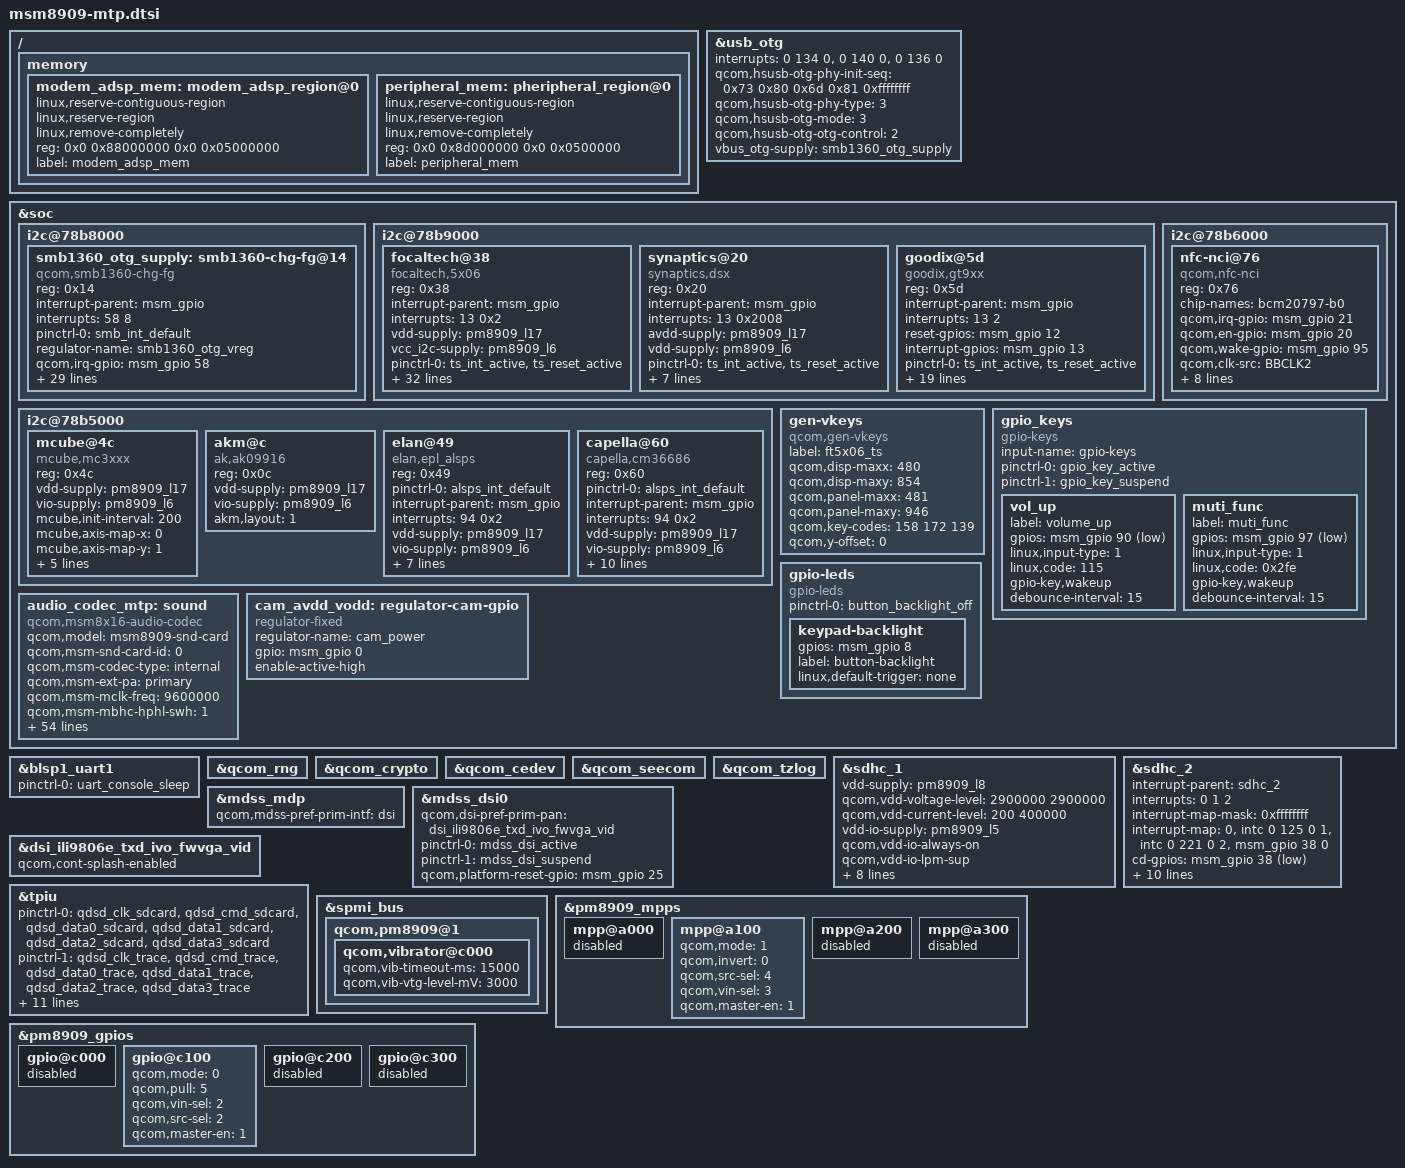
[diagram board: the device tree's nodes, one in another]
/* Copyright (c) 2014, The Linux Foundation. All rights reserved.
 *
 * This program is free software; you can redistribute it and/or modify
 * it under the terms of the GNU General Public License version 2 and
 * only version 2 as published by the Free Software Foundation.
 *
 * This program is distributed in the hope that it will be useful,
 * but WITHOUT ANY WARRANTY; without even the implied warranty of
 * MERCHANTABILITY or FITNESS FOR A PARTICULAR PURPOSE.  See the
 * GNU General Public License for more details.
 */

#include "msm8909-pinctrl.dtsi"
#include "msm8909-camera-sensor-mtp.dtsi"
#include "dsi-panel-ili9806e-txd-ivo-fwvga-video.dtsi"

/ {
	memory {
		#address-cells = <2>;
		#size-cells = <2>;

		modem_adsp_mem: modem_adsp_region@0 {
			linux,reserve-contiguous-region;
			linux,reserve-region;
			linux,remove-completely;
			reg = <0x0 0x88000000 0x0 0x05000000>;
			label = "modem_adsp_mem";
		};

		peripheral_mem: pheripheral_region@0 {
			linux,reserve-contiguous-region;
			linux,reserve-region;
			linux,remove-completely;
			reg = <0x0 0x8d000000 0x0 0x0500000>;
			label = "peripheral_mem";
		};
	};
};

&usb_otg {
    interrupts = <0 134 0>,<0 140 0>,<0 136 0>;
    interrupt-names = "core_irq", "async_irq", "phy_irq";

    qcom,hsusb-otg-phy-init-seq = <0x73 0x80 0x6d 0x81 0xffffffff>;
    qcom,hsusb-otg-phy-type = <3>; /* SNPS Femto PHY */
    qcom,hsusb-otg-mode = <3>; /* USB OTG */
    qcom,hsusb-otg-otg-control = <2>; /* PMIC */
    vbus_otg-supply = <&smb1360_otg_supply>;
};

&soc {
	i2c@78b8000 {
		smb1360_otg_supply: smb1360-chg-fg@14 {
			compatible = "qcom,smb1360-chg-fg";
			reg = <0x14>;
			interrupt-parent = <&msm_gpio>;
			interrupts = <58 8>;
			pinctrl-names = "default";
			pinctrl-0 = <&smb_int_default>;
			regulator-name = "smb1360_otg_vreg";
			qcom,irq-gpio = <&msm_gpio 58 0x8>;
			qcom,chg-inhibit-disabled;
			qcom,rsense-10mhom;
			qcom,otg-batt-curr-limit = <1500>;
			qcom,otg-batt-uvlo-thresh = <3300>;
			qcom,cpu0-sensor-name = "tsens_tz_sensor3";
			qcom,qpnp-vadc = <&pm8909_vadc>;
			qcom,float-voltage-mv = <4350>;
			qcom,iterm-ma = <100>;
			qcom,recharge-thresh-mv = <100>;
			qcom,thermal-mitigation = <1500 700 600 0>;
			qcom,charging-timeout = <1536>;
			qcom,fg-cutoff-voltage-mv = <3400>;
			qcom,fg-voltage-empty-mv = <3250>;
			qcom,fg-batt-capacity-mah = <3000>;
			qcom,fg-cc-soc-coeff = <0x8176>;
			qcom,fg-auto-recharge-soc = <99>;
			qcom,fg-reset-thresold-mv = <50>;
			qcom,shdn-after-pwroff;
			qcom,fg-reset-at-pon;
			qcom,config-hard-thresholds;
			qcom,cold-bat-decidegc = <(-80)>;
			qcom,hot-bat-decidegc = <560>;
			qcom,soft-jeita-supported;
			qcom,warm-bat-decidegc = <450>;
			qcom,cool-bat-decidegc = <100>;
			qcom,cool-bat-mv = <4350>;
			qcom,warm-bat-mv = <4350>;
			qcom,cool-bat-ma = <600>;
			qcom,warm-bat-ma = <900>;
		};
	};
	i2c@78b9000 { /* BLSP1 QUP5 */
		focaltech@38 {
			compatible = "focaltech,5x06";
			reg = <0x38>;
			interrupt-parent = <&msm_gpio>;
			interrupts = <13 0x2>;
			vdd-supply = <&pm8909_l17>;
			vcc_i2c-supply = <&pm8909_l6>;
			/* pins used by touchscreen */
			pinctrl-names = "pmx_ts_active","pmx_ts_suspend";
			pinctrl-0 = <&ts_int_active &ts_reset_active>;
			pinctrl-1 = <&ts_int_suspend &ts_reset_suspend>;
			focaltech,name = "focaltech";
			focaltech,family-id = <0x54>;
			focaltech,reset-gpio = <&msm_gpio 12 0x0>;
			focaltech,irq-gpio = <&msm_gpio 13 0x2>;
			focaltech,display-coords = <0 0 480 854>;
			focaltech,panel-coords = <0 0 481 946>;
			focaltech,button-map= <139 172 158>;
			focaltech,gesture-func-map = <509 510 511 512 513 514 515 516 520 518>;
			focaltech,gesture-figure-map = <0x24 0x52 0x51 0x30 0x54 0x31 0x46 0x41 0x32 0x53>;
			focaltech,gesture-reg-map = <0xd1 0xd2 0xd5 0xd6 0xd7 0xd8>;
			focaltech,gesture-reg-value-map = <0x30 0x17 0x42 0x1e 0x00 0x20>;
			focaltech,fw-rawdata-range = <0 0>;
			focaltech,no-force-update;
			focaltech,i2c-pull-up;
			focaltech,group-id = <1>;
			focaltech,hard-reset-delay-ms = <5>;
			focaltech,soft-reset-delay-ms = <200>;
			focaltech,num-max-touches = <5>;
			focaltech,fw-name = "fw_ft5x06_0xFF.bin";
			focaltech,fw-delay-aa-ms = <2>;
			focaltech,fw-delay-55-ms = <2>;
			focaltech,fw-upgrade-id1 = <0x54>;
			focaltech,fw-upgrade-id2 = <0x2C>;
			focaltech,fw-delay-readid-ms = <20>;
			focaltech,fw-delay-era-flsh-ms = <3000>;
			focaltech,fw-panelid-command = [03 00 d7 84];
			focaltech,touch-area-param = <7>;
		};
		synaptics@20 {
			compatible = "synaptics,dsx";
			reg = <0x20>;
			interrupt-parent = <&msm_gpio>;
			interrupts = <13 0x2008>;
			avdd-supply = <&pm8909_l17>;
			vdd-supply = <&pm8909_l6>;
			/* pins used by touchscreen */
			pinctrl-names = "pmx_ts_active","pmx_ts_suspend","pmx_ts_release";
			pinctrl-0 = <&ts_int_active &ts_reset_active>;
			pinctrl-1 = <&ts_int_suspend &ts_reset_suspend>;
			pinctrl-2 = <&ts_release>;
			synaptics,irq-gpio = <&msm_gpio 13 0x2008>;
			synaptics,reset-gpio = <&msm_gpio 12 0x0>;
			synaptics,disable-gpios;
			synaptics,display-coords = <0 0 719 1279>;
			synaptics,panel-coords = <0 0 719 1405>;
		};
		goodix@5d {
			compatible = "goodix,gt9xx";
			reg = <0x5d>;
			interrupt-parent = <&msm_gpio>;
			interrupts = <13 2>;
			reset-gpios = <&msm_gpio 12 0x00>;
			interrupt-gpios = <&msm_gpio 13 0x00>;
			pinctrl-names = "pmx_ts_active","pmx_ts_suspend";
			pinctrl-0 = <&ts_int_active &ts_reset_active>;
			pinctrl-1 = <&ts_int_suspend &ts_reset_suspend>;
			vdd-supply = <&pm8909_l17>;
			vcc-i2c-supply = <&pm8909_l6>;
			goodix,panel-coords = <0 0 720 1280>;
			goodix,display-coords = <0 0 720 1280>;
			goodix,button-map= <139 172 158>;
			goodix,gesture-map = <509 510 511 512 513 514 515 516 517 518>;
			goodix,gesture-key = <0xCC 0x3E 0x63 0x6F 0x76 0x77 0x73 0x7A 0x6D 0x5E>;//double tap,>,c,o,v,w,s,z,m,^
			goodix,product-id = "9157";	
			goodix,cfg-data1 = [/* dijing */
				4A D0 02 00 05 0A 35 41 01 42 28 0C 53 35 03 07 00 00 1F 7E 00 00 06 12 18 1E 14 8B 0A 0C 34 00 D3 07 00 00 00 BA 33 11 3C 01 00 00 00 00 00 00 00 00 2A 31 4E 54 C5 01 00 14 00 04 82 33 00 79 38 00 71 3D 00 6A 43 00 64 4A 00 64 10 38 50 00 F0 4A 3A FF FF 27 00 00 00 00 00 00 00 00 00 00 00 00 00 0A 14 04 05 10 32 64 09 14 00 00 4B 32 02 04 06 08 0A 0C 0E 10 12 14 16 18 FF FF 00 00 00 00 00 00 00 00 00 00 00 23 00 02 00 00 1E 1F 1D 20 1C 21 18 22 24 16 13 0A 08 12 06 10 04 0F 02 0C 00 FF FF FF FF FF 00 00 00 F6 FF FF FF FF FF FF FF FF 8F FF FF FF 5A 01];

			goodix,cfg-data2 = [/* zhenghai */
				48 D0 02 00 05 05 35 41 01 42 28 0C 55 37 03 07 00 00 1F 7E 00 00 06 12 18 1E 14 8B 0A 0C 34 00 D3 07 00 00 00 BA 33 11 3C 01 00 00 00 00 00 00 00 00 2A 31 4E 54 C5 01 00 14 00 04 82 33 00 79 38 00 71 3D 00 6A 43 00 64 4A 00 64 10 38 50 00 F0 4A 3A FF FF 27 00 00 00 00 00 00 00 00 00 00 00 00 00 0A 0F 04 26 00 21 84 0C 14 00 00 4B 32 02 04 06 08 0A 0C 0E 10 12 14 16 18 FF FF 1F FF FF FF FF FF FF FF FF 00 00 23 00 02 FF 00 24 16 22 18 21 1C 20 1D 1E 1F 13 02 04 12 06 10 08 0F 0A 0C 00 FF FF FF FF FF 00 00 00 F4 FF FF FF FF FF FF FF FF 4F FF FF FF 6B 01];
			goodix,test-data1 = [/* dijing */
 				 41 D0 02 00 05 0A 05 41 01 08 28 05 50 32 03 05 00 00 00 00 00 00 00 00 00 00 00 8B 2A 0C 5B 5E 61 07 00 00 00 98 03 2D 00 00 00 00 00 00 00 00 00 00 00 00 00 00 40 00 00 00 00 00 00 00 00 00 00 00 00 00 00 00 00 00 00 00 00 00 10 38 50 00 F0 4A 3A FF FF 27 00 00 00 00 00 00 00 00 00 00 00 00 00 00 00 00 00 00 00 00 00 00 00 00 00 00 02 04 06 08 0A 0C 0E 10 12 14 16 18 FF FF 00 00 00 00 00 00 00 00 00 FF 00 00 00 00 FF 00 1E 1F 1D 20 1C 21 18 22 16 24 13 0A 08 12 06 10 04 0F 02 0C 00 FF FF FF FF FF FF 00 00 FB 00 01 F0 11 00 FF 00 11 E1 00 00 00 A4 01];

			goodix,test-data2 = [/* zhenghai */
				 00 D0 02 38 04 05 05 41 01 08 28 05 50 32 03 05 00 00 00 00 00 00 00 00 00 00 00 8B 0A 0C 79 7B D3 07 00 00 00 99 03 11 00 00 00 00 00 00 00 00 00 00 00 00 00 00 40 00 00 00 00 00 00 00 00 00 00 00 00 00 00 00 00 00 00 00 00 00 10 38 50 00 F0 4A 3A FF FF 27 00 00 00 00 00 00 00 00 00 00 00 00 00 00 00 00 00 00 00 00 00 00 00 00 00 00 02 04 06 08 0A 0C 0E 10 12 14 16 18 FF FF 1F FF FF FF FF FF FF FF FF 00 FF FF FF FF FF 00 24 16 22 18 21 1C 20 1D 1E 1F 13 02 04 12 06 10 08 0F 0A 0C 00 FF FF FF FF FF 00 FF FF FB FF FF FF FF FF FF FF FF BF FF FF FF 6D 01];
		};
	};

	i2c@78b6000 { /* BLSP1 QUP2 */
			nfc-nci@76 {
			compatible = "qcom,nfc-nci";
			reg = <0x76>;
			chip-names = "bcm20797-b0";
			qcom,irq-gpio = <&msm_gpio 21 0x00>;
			qcom,en-gpio = <&msm_gpio 20 0x00>;
			qcom,wake-gpio = <&msm_gpio 95 0x00>;
			qcom,clk-src = "BBCLK2";
			interrupt-parent = <&msm_gpio>;
			interrupts = <21 0>;
			interrupt-names = "nfc_irq";
			pinctrl-names = "nfc_active","nfc_suspend";
			pinctrl-0 = <&nfc_int_active &nfc_disable_active &nfc_wake_active>;
			pinctrl-1 = <&nfc_int_suspend &nfc_disable_suspend &nfc_wake_suspend>;
			qcom,clk-gpio = <&pm8909_gpios 2 0x00>;
			clocks = <&clock_rpm clk_bb_clk2_pin>;
			clock-names = "ref_clk";
		};
	};

	i2c@78b5000 { /* BLSP1 QUP1 */
		mcube@4c {
			compatible = "mcube,mc3xxx";
			reg = <0x4c>;
			vdd-supply = <&pm8909_l17>;
			vio-supply = <&pm8909_l6>;
			mcube,init-interval = <200>;
			mcube,axis-map-x = <0>;
			mcube,axis-map-y = <1>;
			mcube,axis-map-z = <2>;
			mcube,g-range = <8>;
			mcube,negate-x;
			/*mcube,negate-y;*/
			mcube,negate-z;
			mcube,res-14bit;
		};
		akm@c {/* Akm field sensor */
			compatible = "ak,ak09916";
			reg = <0x0c>;
			vdd-supply = <&pm8909_l17>;
			vio-supply = <&pm8909_l6>;
			akm,layout = <1>;
		};
		elan@49 {
			compatible = "elan,epl_alsps";
			reg = <0x49>;
			pinctrl-names = "default";
			pinctrl-0 = <&alsps_int_default>;
			interrupt-parent = <&msm_gpio>;
			interrupts = <94 0x2>;
			vdd-supply = <&pm8909_l17>;
			vio-supply = <&pm8909_l6>;
			epl,irq-gpio = <&msm_gpio 94 0x2>;
			epl,ps_close_thd_set = <3000>;
			epl,ps_away_thd_set = <1000>;
			epl,ps_crosstalk_max = <500>;
			epl,als_fittness = <10>;
			epl,als_numerator = <52>;
			epl,als_root = <100>;
		};

		capella@60 {
			compatible = "capella,cm36686";
			reg = <0x60>;
			pinctrl-names = "default";
			pinctrl-0 = <&alsps_int_default>;
			interrupt-parent = <&msm_gpio>;
			interrupts = <94 0x2>;
			vdd-supply = <&pm8909_l17>;
			vio-supply = <&pm8909_l6>;
			capella,interrupt-gpio =<&msm_gpio 94 0x2>;
			capella,ps_duty = <0>;
			/*
			 * CM36283 & CM36686
			 * 0 -- 1/40; 1 -- 1/80; 2 -- 1/160; 3 -- 1/320;
			 */
			capella,ps_it = <2>;
			/*
			 *CM3686
			 * Default set to 1.
			 * 0 -- 1T; 1 -- 1.5T; 2 -- 2T; 3 -- 2.5T;
			 * 4 -- 3T; 5 -- 3.5T; 6 -- 4T; 7 -- 8T;
			 */
			capella,ps_led_drv = <2>;
			/*
			 * This para in CM36686
			 * Default set to 2.
			 * 0 -- 50mA; 1 -- 75mA; 2 -- 100mA; 3 -- 120mA;
			 * 4 -- 140mA; 5 -- 160mA; 6 -- 180mA; 7 -- 200mA;
			 */
			capella,ps_close_thd_set = <45>;
			capella,ps_away_thd_set = <15>;
			capella,als_range = <0>;
			/*
			 * 0 -- 80ms; 1 -- 160ms; 2 -- 320ms; 3 -- 640ms;
			 * Dividor:
			 * CM36283, 80;
			 * CM36682, 100;
			 * CM36686, 100.
			 */
			capella,als_fittness = <10>;
			/*
			 * This para using for fix the mechinical diff about TP lens.
			 * Default set to 10.
			 */
			capella,ps_crosstalk_max = <70>;
			capella,ps_crosstalk_min = <0>;
		};
	};

	gen-vkeys {
		compatible = "qcom,gen-vkeys";
		label = "ft5x06_ts";
		qcom,disp-maxx = <480>;
		qcom,disp-maxy = <854>;
		qcom,panel-maxx = <481>;
		qcom,panel-maxy = <946>;
		qcom,key-codes = <158 172 139>;
		qcom,y-offset = <0>;
	};

	gpio_keys {
		compatible = "gpio-keys";
		input-name = "gpio-keys";
		pinctrl-names = "tlmm_gpio_key_active","tlmm_gpio_key_suspend";
		pinctrl-0 = <&gpio_key_active>;
		pinctrl-1 = <&gpio_key_suspend>;

		vol_up {
			label = "volume_up";
			gpios = <&msm_gpio 90 0x1>;
			linux,input-type = <1>;
			linux,code = <115>;
			gpio-key,wakeup;
			debounce-interval = <15>;
		};

		muti_func {
			label = "muti_func";
			gpios = <&msm_gpio 97 0x1>;
			linux,input-type = <1>;
			linux,code = <0x2fe>;
			gpio-key,wakeup;
			debounce-interval = <15>;
		};
	};

	gpio-leds {
		compatible = "gpio-leds";
		status = "ok";
		pinctrl-names = "default";
		pinctrl-0 = <&button_backlight_off>;
		keypad-backlight {
			gpios = <&msm_gpio 8 0x00>;
			label = "button-backlight";
			linux,default-trigger = "none";
		};
	};

	audio_codec_mtp: sound {
		compatible = "qcom,msm8x16-audio-codec";
		qcom,model = "msm8909-snd-card";
		qcom,msm-snd-card-id = <0>;
		qcom,msm-codec-type = "internal";
		qcom,msm-ext-pa = "primary";
		qcom,msm-mclk-freq = <9600000>;
		qcom,msm-mbhc-hphl-swh = <1>;
		qcom,msm-mbhc-gnd-swh = <0>;
		qcom,msm-hs-micbias-type = "external";
		qcom,msm-micbias1-ext-cap;
		qcom,msm-micbias2-ext-cap;
		qcom,audio-routing =
			"RX_BIAS", "MCLK",
			"SPK_RX_BIAS", "MCLK",
			"INT_LDO_H", "MCLK",
			"MIC BIAS External", "Handset Mic",
			"MIC BIAS External2", "Headset Mic",
			"MIC BIAS External", "Secondary Mic",
			"AMIC1", "MIC BIAS External",
			"AMIC2", "MIC BIAS External2",
			"AMIC3", "MIC BIAS External";
		pinctrl-names = "cdc_lines_act",
				"cdc_lines_sus",
				"ext_spk_pa_act",
				"ext_spk_pa_sus",
				"headset_switch_act",
				"headset_switch_sus";
		pinctrl-0 = <&cdc_pdm_lines_act>;
		pinctrl-1 = <&cdc_pdm_lines_sus>;
		pinctrl-2 = <&ext_spk_pa_act>;
		pinctrl-3 = <&ext_spk_pa_sus>;
		pinctrl-4 = <&headset_switch_act>;
		pinctrl-5 = <&headset_switch_sus>;
		qcom,ext-spk-pa-gpio = <&msm_gpio 98 0>;
		qcom,headset-switch-gpio = <&msm_gpio 11 0>;
		asoc-platform = <&pcm0>, <&pcm1>, <&voip>, <&voice>,
				<&loopback>, <&compress>, <&hostless>,
				<&afe>, <&lsm>, <&routing>, <&lpa>,
				<&voice_svc>;
		asoc-platform-names = "msm-pcm-dsp.0", "msm-pcm-dsp.1",
				"msm-voip-dsp", "msm-pcm-voice", "msm-pcm-loopback",
				"msm-compress-dsp", "msm-pcm-hostless", "msm-pcm-afe",
				"msm-lsm-client", "msm-pcm-routing", "msm-pcm-lpa",
				"msm-voice-svc";
		asoc-cpu = <&dai_pri_auxpcm>, <&dai_hdmi>,
				<&dai_mi2s0>, <&dai_mi2s1>, <&dai_mi2s2>, <&dai_mi2s3>,
				<&sb_0_rx>, <&sb_0_tx>, <&sb_1_rx>, <&sb_1_tx>,
				<&sb_3_rx>, <&sb_3_tx>, <&sb_4_rx>, <&sb_4_tx>,
				<&bt_sco_rx>, <&bt_sco_tx>,<&bt_a2dp_rx>,
                                <&int_fm_rx>, <&int_fm_tx>,
				<&afe_pcm_rx>, <&afe_pcm_tx>, <&afe_proxy_rx>, <&afe_proxy_tx>,
				<&incall_record_rx>, <&incall_record_tx>, <&incall_music_rx>,
				<&incall_music_2_rx>;
		asoc-cpu-names = "msm-dai-q6-auxpcm.1", "msm-dai-q6-hdmi.8",
				"msm-dai-q6-mi2s.0", "msm-dai-q6-mi2s.1",
				"msm-dai-q6-mi2s.2", "msm-dai-q6-mi2s.3",
				"msm-dai-q6-dev.16384", "msm-dai-q6-dev.16385",
				"msm-dai-q6-dev.16386", "msm-dai-q6-dev.16387",
				"msm-dai-q6-dev.16390", "msm-dai-q6-dev.16391",
				"msm-dai-q6-dev.16392", "msm-dai-q6-dev.16393",
				"msm-dai-q6-dev.12288", "msm-dai-q6-dev.12289",
				"msm-dai-q6-dev.12290", "msm-dai-q6-dev.12292",
                                "msm-dai-q6-dev.12293", "msm-dai-q6-dev.224",
				"msm-dai-q6-dev.225", "msm-dai-q6-dev.241",
				"msm-dai-q6-dev.240", "msm-dai-q6-dev.32771",
				"msm-dai-q6-dev.32772", "msm-dai-q6-dev.32773",
				"msm-dai-q6-dev.32770";
		asoc-codec = <&stub_codec>, <&pm8909_conga_dig>;
		asoc-codec-names = "msm-stub-codec.1", "tombak_codec";
	};
	
	cam_avdd_vodd: regulator-cam-gpio {   //jp add
		compatible = "regulator-fixed";
	        regulator-name = "cam_power";
		//regulator-min-microvolt = <1800000>;////jp  invalid?
		//regulator-max-microvolt = <1800000>;////jp  invalid?
		gpio = <&msm_gpio 0 0>;///jp 0 mean low ?
		enable-active-high;
	};
	
	
	
	
};

&blsp1_uart1 {
	status = "ok";
	pinctrl-names = "default";
	pinctrl-0 = <&uart_console_sleep>;
};



&qcom_rng {
	status = "okay";
};

&qcom_crypto {
	status = "okay";
};

&qcom_cedev {
	status = "okay";
};

&qcom_seecom {
	status = "okay";
};

&qcom_tzlog {
	status = "okay";
};

&sdhc_1 {
	vdd-supply = <&pm8909_l8>;
	qcom,vdd-voltage-level = <2900000 2900000>;
	qcom,vdd-current-level = <200 400000>;

	vdd-io-supply = <&pm8909_l5>;
	qcom,vdd-io-always-on;
	qcom,vdd-io-lpm-sup;
	qcom,vdd-io-voltage-level = <1800000 1800000>;
	qcom,vdd-io-current-level = <200 60000>;

	pinctrl-names = "active", "sleep";
	pinctrl-0 = <&sdc1_clk_on &sdc1_cmd_on &sdc1_data_on>;
	pinctrl-1 = <&sdc1_clk_off &sdc1_cmd_off &sdc1_data_off>;

	qcom,bus-speed-mode = "HS200_1p8v", "DDR_1p8v";
	qcom,nonremovable;

	status = "ok";
};

&sdhc_2 {
	 #address-cells = <0>;
	interrupt-parent = <&sdhc_2>;
	interrupts = <0 1 2>;
	#interrupt-cells = <1>;
	interrupt-map-mask = <0xffffffff>;
	interrupt-map = <0 &intc 0 125 0
			1 &intc 0 221 0
			2 &msm_gpio 38 0>;
	interrupt-names = "hc_irq", "pwr_irq", "status_irq";
	cd-gpios = <&msm_gpio 38 0x1>;
	
	vdd-supply = <&pm8909_l11>;
	qcom,vdd-voltage-level = <1800000 2950000>;
	qcom,vdd-current-level = <15000 400000>;

	vdd-io-supply = <&pm8909_l12>;
	qcom,vdd-io-voltage-level = <1800000 2950000>;
	qcom,vdd-io-current-level = <200 50000>;

	pinctrl-names = "active", "sleep";
	pinctrl-0 = <&sdc2_clk_on &sdc2_cmd_on &sdc2_data_on &sdc2_cd_on>;
	pinctrl-1 = <&sdc2_clk_off &sdc2_cmd_off &sdc2_data_off &sdc2_cd_off>;
	status = "ok";
};

&mdss_mdp {
	qcom,mdss-pref-prim-intf = "dsi";
};

&mdss_dsi0 {
	qcom,dsi-pref-prim-pan = <&dsi_ili9806e_txd_ivo_fwvga_vid>;
	pinctrl-names = "mdss_default", "mdss_sleep";
	pinctrl-0 = <&mdss_dsi_active>;//&mdss_te_active
	pinctrl-1 = <&mdss_dsi_suspend>;//&mdss_te_suspend

	qcom,platform-reset-gpio = <&msm_gpio 25 0>;
};

&dsi_ili9806e_txd_ivo_fwvga_vid {
       qcom,cont-splash-enabled;
};

/* CoreSight */
&tpiu {
	pinctrl-names = "sdcard", "trace", "swduart",
			"swdtrc", "jtag", "spmi";
	/* NIDnT */
	pinctrl-0 = <&qdsd_clk_sdcard &qdsd_cmd_sdcard
		     &qdsd_data0_sdcard &qdsd_data1_sdcard
		     &qdsd_data2_sdcard &qdsd_data3_sdcard>;
	pinctrl-1 = <&qdsd_clk_trace &qdsd_cmd_trace
		     &qdsd_data0_trace &qdsd_data1_trace
		     &qdsd_data2_trace &qdsd_data3_trace>;
	pinctrl-2 = <&qdsd_cmd_swduart &qdsd_data0_swduart
		     &qdsd_data1_swduart &qdsd_data2_swduart
		     &qdsd_data3_swduart>;
	pinctrl-3 = <&qdsd_clk_swdtrc &qdsd_cmd_swdtrc
		     &qdsd_data0_swdtrc &qdsd_data1_swdtrc
		     &qdsd_data2_swdtrc &qdsd_data3_swdtrc>;
	pinctrl-4 = <&qdsd_cmd_jtag &qdsd_data0_jtag
		     &qdsd_data1_jtag &qdsd_data2_jtag
		     &qdsd_data3_jtag>;
	pinctrl-5 = <&qdsd_clk_spmi &qdsd_cmd_spmi
		     &qdsd_data0_spmi &qdsd_data3_spmi>;
};
&spmi_bus {
	qcom,pm8909@1 {
		qcom,vibrator@c000 {
			status = "okay";
			qcom,vib-timeout-ms = <15000>;
			qcom,vib-vtg-level-mV = <3000>;
		};
	};
};

&pm8909_mpps {
	mpp@a000 { /* MPP 1 */
		/* VDD_PX */
		status = "disabled";
	};

	mpp@a100 { /* MPP 2 */
		/* Backlight PWM */
		qcom,mode = <1>;		/* Digital output */
		qcom,invert = <0>;		/* Disable invert */
		qcom,src-sel = <4>;		/* DTEST1 */
		qcom,vin-sel = <3>;		/* VPH_PWR */
		qcom,master-en = <1>;		/* Enable MPP */
	};

	mpp@a200 { /* MPP 3 */
		/* VREF DAC */
		status = "disabled";
	};

	mpp@a300 { /* MPP 4 */
		/* HR LED */
		status = "disabled";
	};
};

&pm8909_gpios {
	gpio@c000 { /* GPIO 1 */
		/* Battery UICC Alarm */
		status = "disabled";
	};

	gpio@c100 { /* GPIO 2 */
		/* NFC_CLK_REQ */
		qcom,mode = <0>; /* QPNP_PIN_MODE_DIG_IN */
		qcom,pull = <5>; /* QPNP_PIN_PULL_NO */
		qcom,vin-sel = <2>; /* QPNP_PIN_VIN2 */
		qcom,src-sel = <2>; /* QPNP_PIN_SEL_FUNC_1 */
		qcom,master-en = <1>;
	};

	gpio@c200 { /* GPIO 3 */
		/* External regulator control for WTR */
		status = "disabled";
	};

	gpio@c300 { /* GPIO 4 */
		/* External regulator control for APC */
		status = "disabled";
	};
};

&audio_codec_mtp {
	qcom,msm-micbias2-ext-cap;
};
